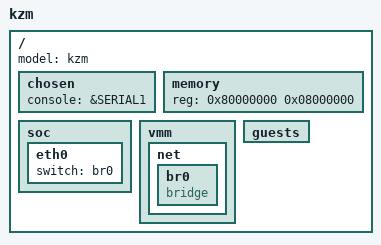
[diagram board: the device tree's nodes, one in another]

/include/ "../imx31.dtsi"

/ {
	model = "kzm";

	chosen {
		console = &SERIAL1;
	};

	memory {
		device_type = "memory"; 
		reg = <0x80000000 0x08000000>; /* 128 MB */
	};

	soc {
		eth0 {
			switch = "br0";
		};
	};

	vmm {
		net {
			br0 {
				device_type = "netswitch";
				compatible = "bridge";
			};
		};
	};

	/* Empty guests node */
	guests {
	};
};

/* Add guest templates */
/include/ "../../../common/guests/realview-eb-mpcore.dtsi"

